# RX64M_USBA_Pilot register map
File version: 1.0
RX64M_USBA_Pilot peripheral registers generated from iodefine.h (pilot).
Registers are 16-bit, read-write, reset 0x0 unless marked. A register's access mark holds for its fields unless they carry their own. Offsets are from the block's base; lines under a group give offsets from that group; [hi:lo] are bit positions; {n}, {i} and the like mark numbered series; 'fields as' and 'values as' point back to an identical list; <NAME> marks a mode.

## Memory map
0x000D0400 USBA size 0x168

## USBA
Base 0x000D0400
0x00 SYSCFG reset 0x20 (reset mask 0x1F1)
0x02 BUSWAIT reset 0xF0F (reset mask 0x3F3F)
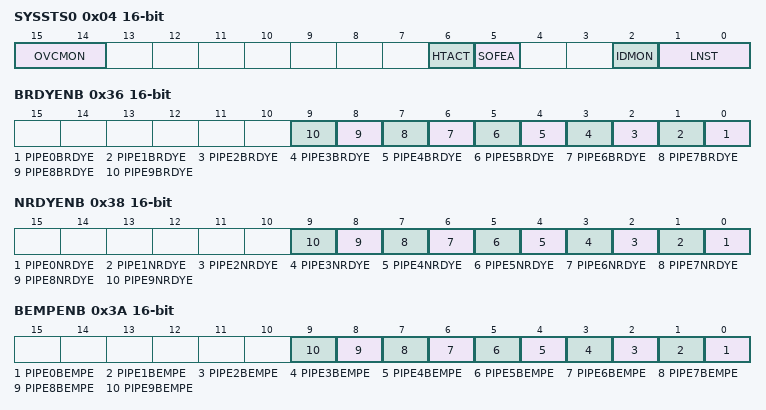
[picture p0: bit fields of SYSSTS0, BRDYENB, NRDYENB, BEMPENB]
0x04 SYSSTS0 ro (reset mask 0x60)
  [15:14] OVCMON, [6] HTACT, [5] SOFEA, [2] IDMON, [1:0] LNST
0x06 PLLSTA ro
  [0] PLLLOCK
0x08 DVSTCTR0 (reset mask 0xFF7)
0x14 CFIFO 32-bit
0x18 D0FIFO 32-bit
0x1C D1FIFO 32-bit
0x20 CFIFOSEL (reset mask 0xCD2F)
0x22 CFIFOCTR (reset mask 0xEFFF)
0x28 D0FIFOSEL (reset mask 0xFD0F)
0x2A D0FIFOCTR (reset mask 0xEFFF)
0x2C D1FIFOSEL (reset mask 0xFD0F)
0x2E D1FIFOCTR (reset mask 0xEFFF)
0x30 INTENB0 (reset mask 0xFF00)
0x32 INTENB1 (reset mask 0xDB71)
0x36 BRDYENB
  [n] PIPE{n}BRDYE (n=0..9)
0x38 NRDYENB
  [n] PIPE{n}NRDYE (n=0..9)
0x3A BEMPENB
  [n] PIPE{n}BEMPE (n=0..9)
0x3C SOFCFG (reset mask 0x170)
0x3E PHYSET reset 0x33
0x40 INTSTS0 (reset mask 0xFF7F)
0x42 INTSTS1 (reset mask 0xDB71)
0x46 BRDYSTS
0x48 NRDYSTS
0x4A BEMPSTS
0x4C FRMNUM (reset mask 0xC7FF)
0x50 USBADDR ro
  [6:0] USBADDR
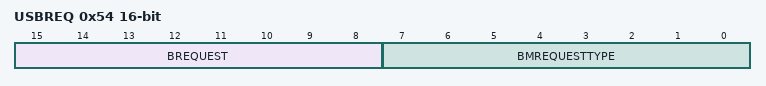
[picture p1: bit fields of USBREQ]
0x54 USBREQ
  [15:8] BREQUEST, [7:0] BMREQUESTTYPE
0x56 USBVAL
0x58 USBINDX
0x5A USBLENG
0x5C DCPCFG (reset mask 0x190)
0x5E DCPMAXP reset 0x40 (reset mask 0xF07F)
0x60 DCPCTR (reset mask 0xE9E7)
0x64 PIPESEL (reset mask 0xF)
0x68 PIPECFG
0x6A PIPEBUF
0x6C PIPEMAXP
0x6E PIPEPERI
{0x6E+2i} PIPE{i}CTR reset 0x40 (reset mask 0xC7E3) (i=1..9)
{0x8C+4i} PIPE{i}TRE (reset mask 0x300) (i=1..5)
{0x8E+4i} PIPE{i}TRN (i=1..5)
  [15:0] TRNCNT
{0xD0+2i} DEVADD{i} (reset mask 0xC0) (i=0..5)
0x100 LPCTRL (reset mask 0x180)
0x102 LPSTS (reset mask 0x510B)
0x140 BCCTRL
0x144 PL1CTRL1 (reset mask 0x4FFF)
0x146 PL1CTRL2 (reset mask 0x1F00)
0x148 HL1CTRL1 (reset mask 0x7)
0x14A HL1CTRL2 (reset mask 0x9F0F)
0x160 DPUSR0R 32-bit
0x164 DPUSR1R 32-bit
